AUTOSAR XML (schema 4-2-2)
package /C/DT
  data transformation set TC
    data transformation DT_CAN_LIN: transformer-chain=T1
    data transformation DT_Ethernet: transformer-chain=T2
    transformation technology T1: protocol=E2E, end-to-end-transformation-description{counter-offset=12, crc-offset=0, max-no-new-or-repeated-data=5, sync-counter-init=0}, transformer-class=SERIALIZER, version=1.0.0
    transformation technology T2: protocol=E2E, end-to-end-transformation-description{counter-offset=16, crc-offset=0, max-no-new-or-repeated-data=5, sync-counter-init=0}, transformer-class=SERIALIZER, version=1.0.0
package /C/Diagnostics
  elements:
    functional-request=FuncReq, physical-request=DoIP_Tp_ICU_PhyRequest, response=DoIP_Tp_ICU_PhyResponse
    functional-request=FuncReq, physical-request=PhyReq, response=DoIP_Tp_ICU_GW_AMP_PhyResponse
package /C/NetworkManagement
  nm config ADI
    can nm cluster ADI_CAN_ASR: communication-cluster=ADI_CAN, nm-cbv-position=1, nm-msg-cycle-time=0.5, nm-network-timeout=5, nm-nid-position=0, nm-repeat-message-time=0.5, nm-wait-bus-sleep-time=5
      can nm node AMP: nm-node-id=156, rx-nm-pdu=NmADIMessage_ASR, tx-nm-pdu=NmAMPMessage_ASR, nm-car-wake-up-filter-enabled=false, nm-car-wake-up-rx-enabled=false, nm-msg-cycle-offset=0, nm-range-config={lower-can-id=1435, upper-can-id=1436}
      can nm node ICU: controller=ADI_CAN_ICU, nm-coordinator-role=ACTIVE, nm-if-ecu=ICU_ADICAN_ASR, nm-node-id=155, rx-nm-pdu=NmAMPMessage_ASR, tx-nm-pdu=NmADIMessage_ASR, nm-car-wake-up-filter-enabled=false, nm-car-wake-up-rx-enabled=false, nm-range-config={lower-can-id=1435, upper-can-id=1436}
    nm-if-ecus:
      nm ecu ICU_ADICAN_ASR: ecu-instance=Infotainment_Control_Unit, nm-com-control-enabled=true, nm-coordinator={nm-active-coordinator=true, nm-shutdown-delay-timer=5}, nm-cycletime-main-function=0.05, nm-passive-mode-enabled=false
  nm config Ethernet_Backbone
    udp nm cluster Udp_Nm_Cluster1: communication-cluster=Ethernet_Backbone, nm-cbv-position=1, nm-message-timeout-time=5, nm-msg-cycle-time=0.5, nm-network-timeout=5, nm-nid-position=0, nm-remote-sleep-indication-time=0.5, nm-user-data-length=0, nm-wait-bus-sleep-time=0.75
      udp nm node ADI: controller=ETH_ICU, nm-if-ecu=ADI, nm-node-id=2, rx-nm-pdu=[NmTCUMessage, NmZA1Message], tx-nm-pdu=NmADIMessage, nm-msg-cycle-offset=0
    nm-if-ecus:
      nm ecu ADI: ecu-instance=Infotainment_Control_Unit, nm-coordinator=nm-shutdown-delay-timer=5, nm-cycletime-main-function=0.05, nm-passive-mode-enabled=false
package /C/PDUs
  dcm i pdu DiagFunctionalReq_DcmPDU: length=7, diag-pdu-type=DIAG-REQUEST
  dcm i pdu DiagReqAMP_DCMPDU: length=256, diag-pdu-type=DIAG-REQUEST
  general purpose pdu DoIP_ICU_UDP_Request: category=DoIP, length=8
  general purpose pdu DoIP_ICU_UDP_Response: category=DoIP, length=8
  pdu ACF_State01_PDU: length=2, transmission-mode-true-timing=cyclic-timing={time-offset=0, time-period=0.2}
    transmission-mode-conditions:
      data-filter=data-filter-type=ALWAYS, i-signal-in-i-pdu=BCameraFailureState
      data-filter=data-filter-type=ALWAYS, i-signal-in-i-pdu=NCameraSystemState
    mapping BCameraFailureState: i-signal=IBCameraFailureState, packing-byte-order=little-endian, start-position=0, transfer-property=PENDING
    mapping NCameraSystemState: i-signal=INCameraSystemState, packing-byte-order=little-endian, start-position=1, transfer-property=PENDING
  pdu ACUAlarmStatus_PDU: length=1, transmission-mode-true-timing=cyclic-timing={time-offset=0, time-period=0.1}
    transmission-mode-conditions:
      data-filter=data-filter-type=ALWAYS, i-signal-in-i-pdu=NAlarmStatus
      data-filter=data-filter-type=ALWAYS, i-signal-in-i-pdu=SignalIPDUAssignment21864
    mapping NAlarmStatus: i-signal=INAlarmStatus, packing-byte-order=big-endian, start-position=3, transfer-property=PENDING
    mapping SignalIPDUAssignment21864: i-signal=IBAlarmSystem, packing-byte-order=big-endian, start-position=7, transfer-property=PENDING
  i signal i pdu group ADI_ETH_BODYVLAN_BODY_ISignalIPduGroup_Rx: communication-direction=IN, i-signal-i-pdus=[BdyClusterMessage_PDU, CHMSLClusterMessage_PDU]
  i signal i pdu group ADI_ETH_BODYVLAN_BODY_ISignalIPduGroup_Tx: communication-direction=OUT, i-signal-i-pdus=[NDiffusedAirProfile_PDU, NDriverTempSlider_PDU]
  pdu HEC_MCM_PDU: length=1, transmission-mode-condition{data-filter=data-filter-type=ALWAYS, i-signal-in-i-pdu=Vehicle_SteerWheelPos_Status}, transmission-mode-true-timing=cyclic-timing={time-offset=0, time-period=1}
    mapping Vehicle_SteerWheelPos_Status: i-signal=IVehicle_SteerWheelPos_Status, packing-byte-order=big-endian, start-position=1, transfer-property=PENDING
  pdu HMA_State01_PDU: length=8, transmission-mode-true-timing=cyclic-timing={time-offset=0, time-period=0.04}
    transmission-mode-conditions:
      data-filter=data-filter-type=ALWAYS, i-signal-in-i-pdu=BIHC_HMA_Recommendation
      data-filter=data-filter-type=ALWAYS, i-signal-in-i-pdu=NHMA_State_CRC
    mapping NIHC_HMA_Status: i-signal=INIHC_HMA_Status, packing-byte-order=little-endian, start-position=0, transfer-property=PENDING
    mapping NIHC_HMANoHBReason: i-signal=INIHC_HMANoHBReason, packing-byte-order=little-endian, start-position=4, transfer-property=PENDING
  multiplexed i pdu NCarConfig: length=8, dynamic-part{segment-position{segment-byte-order=big-endian, segment-length=64, segment-position=7}, dynamic-part-alternatives=[{i-pdu=NCarConfig_MX1, selector-field-code=1}, {i-pdu=NCarConfig_MX2, selector-field-code=2}]}, selector-field-byte-order=big-endian, selector-field-length=3, selector-field-start-position=2
  multiplexed i pdu VIN: length=8, dynamic-part{segment-position{segment-byte-order=big-endian, segment-length=64, segment-position=7}, dynamic-part-alternatives=[{i-pdu=VIN_VIN_Bytes_8_14, selector-field-code=1}, {i-pdu=VIN_VIN_Bytes_1_7, initial-dynamic-part=true, selector-field-code=0}]}, selector-field-byte-order=big-endian, selector-field-length=8, selector-field-start-position=7
  n pdu DiagFunctionalReq_NPDU: length=8
  n pdu TestRespAMP_TP: length=8
  nm pdu NmADIMessage: length=2
  nm pdu NmADIMessage_ASR: length=8
  xcp pdu XCP_ESW_GW_RVC_Req_PDU: length=8
  xcp pdu XCP_ESW_GW_RVC_Resp_PDU: length=8
package /C/Signals
  i signal group INCruiseSwitch_Group: i-signal=[INCruiseSwitchChecksum, INCruiseSwitchCounter], system-signal-group=NCruiseSwitch_Group
  i signal group INDriverModeReq_Group: i-signal=[IBESPReducedRequested, INChassisModeEngaged], system-signal-group=NDriverModeReq_Group
  i signal IAMP_Audio_Balance_Status: init-value=Signal_AMP_Audio_Balance_Status:18, length=5, base-type=uint8_M, compu {phys=raw-9 for raw 0..18}, system-signal=AMP_Audio_Balance_Status
  i signal IAMP_Audio_Bass_Status: init-value=Signal_AMP_Audio_Bass_Status:18, length=5, base-type=uint8_M, compu-method=AMP_Audio_Bass_Status_NW, system-signal=AMP_Audio_Bass_Status
package /C/SystemSignals
  system signal AMP_Audio_Balance_Status: compu {phys=raw-9 for raw 0..18}
  system signal AMP_Audio_Bass_Status: compu-method=AMP_Audio_Bass_Status_NW
package /C/TP
  can tp config ADI_CAN: communication-cluster=ADI_CAN, can-tp-ecu=Infotainment_Control_Unit
    can tp channel CAN_Tp_Functional_Channel_ADICAN: channel-mode=FULL-DUPLEX-MODE
    can tp channel CAN_Tp_Physical_Channel_ADICAN: channel-mode=FULL-DUPLEX-MODE
    tp-connections:
      addressing-format=STANDARD, can-tp-channel=CAN_Tp_Functional_Channel_ADICAN, data-pdu=DiagFunctionalReq_NPDU, receiver=[Audio_Amplifier_Highline_ADI_CAN, Rear_View_Camera_ADI_CAN, Surround_View_Camera_Controller_ADI_CAN], ta-type=FUNCTIONAL, tp-sdu=DiagFunctionalReq_DcmPDU, transmitter=Infotainment_Control_Unit_ADI_CAN
      addressing-format=STANDARD, can-tp-channel=CAN_Tp_Physical_Channel_ADICAN, data-pdu=TestRespAMP_TP, flow-control-pdu=TesterReqAMP_TP, receiver=Infotainment_Control_Unit_ADI_CAN, ta-type=PHYSICAL, tp-sdu=DiagRespAMP_DCMPDU, transmitter=Audio_Amplifier_Highline_ADI_CAN
    can tp node Audio_Amplifier_Highline_ADI_CAN
    can tp node Infotainment_Control_Unit_ADI_CAN: connector=Infotainment_Control_Unit_ADI_CAN
  do ip tp config DoIP: communication-cluster=Ethernet_Backbone
    do ip logic address DoIP_ICU_Func: address=58368
    do ip logic address DoIP_ICU_GW_AMP_Func: address=58368
    do-ip-tp-connection do-ip-source-address=DoIP_ICU_GW_AMP_Phy, do-ip-target-address=OBDTester, tp-sdu=DoIpTp_ICU_AMP_PhysResp_DCMPDU_ETH:
      ident DoIP_Tp_ICU_GW_AMP_PhyResponse
    do-ip-tp-connection do-ip-source-address=DoIP_ICU_GW_RVC_Phy, do-ip-target-address=OBDTester, tp-sdu=DoIpTp_ICU_RVC_PhysResp_DCMPDU_ETH:
      ident DoIP_Tp_ICU_GW_RVC_PhyResponse
package /DataConstraints
  range Generic_Internal_Data_Constraint216: raw 0..12000
  range Generic_Internal_Data_Constraint2161: raw 0..12000
package /DataTypeMappingSets
  data type mapping set ADAS_HMI_Coordinator
    data-type-maps:
      application-data-type=BACCOvertakeBoost, implementation-data-type=uint8_M
      application-data-type=BACCOvertakePrevent, implementation-data-type=uint8_M
  data type mapping set ADI_Camera_AMP_Mgr
    data-type-maps:
      application-data-type=AMP_Audio_Balance_Status, implementation-data-type=uint8_M
      application-data-type=AMP_Audio_Bass_Status, implementation-data-type=uint8_M
package /DataTypes/ApplicationDataTypes
  application array data type N_DNS_Server: category=ARRAY, unit=NoUnit1
    element N_DNS_Server: category=ARRAY, type=N_DNS_Server_ArrayElement, array-size-semantics=FIXED-SIZE, max-number-of-elements=255
  application array data type N_DNS_Server_ArrayElement: category=ARRAY, unit=NoUnit1
    element N_DNS_Server_ArrayElement: category=VALUE, type=N_DNS_Server_Element, array-size-semantics=FIXED-SIZE, max-number-of-elements=4
  app type AMP_Audio_Balance_Status: category=VALUE, compu {phys=raw-9 for raw -9..9}, sw-intended-resolution=1.0, unit=NoUnit1
  app type AMP_Audio_Bass_Status: category=VALUE, compu-method=AMP_Audio_Bass_Status, sw-intended-resolution=1.0, unit=NoUnit1
  application record data type NCruiseSwitch_Group: category=STRUCTURE
    application record element NCruiseSwitchStatus: category=VALUE, type=NCruiseSwitchStatus
    application record element NIndicatorRStatus: category=VALUE, type=NIlluminationActiveStatus
  application record data type NDriverModeReq_Group: category=STRUCTURE
    application record element NESPOffRequested: category=VALUE, type=NESPOffRequested
    application record element NESPModeChangeReq: category=VALUE, type=N2ModeChangeRequested
package /DataTypes/BaseTypes
  sw addr method CONST_VOLATILE
  base type uint16_M: category=FIXED_LENGTH, base-type-size=16, base-type-encoding=NONE, mem-alignment=0, byte-order=big-endian, native-declaration=uint16
  base type uint32_M: category=FIXED_LENGTH, base-type-size=32, base-type-encoding=NONE, mem-alignment=0, byte-order=big-endian, native-declaration=uint32
package /DataTypes/ImplementationDataTypes
  impl type BESPReducedRequested: category=VALUE, sw-alignment=0, base-type=uint8_M, data-constr=uint81, sw-refresh-timing={cse-code=3, cse-code-factor=0}
  impl type NChassisModeEngaged: category=VALUE, sw-alignment=0, base-type=uint8_M, data-constr=uint8_M25, sw-refresh-timing={cse-code=3, cse-code-factor=0}
package /DataTypes/ModelManagement
  mode declaration group Body_LIN_Sch_Switch: category=ALPHABETIC_ORDER, initial-mode=BodyLINSchedule_Normal, on-transition-value=3
    mode BodyLINSchedule_LVHV: value=2
    mode BodyLINSchedule_Normal: value=1
    mode transition LVHV_to_Normal: entered-mode=BodyLINSchedule_Normal, exited-mode=BodyLINSchedule_LVHV
    mode transition Normal_to_LVHV: entered-mode=BodyLINSchedule_LVHV, exited-mode=BodyLINSchedule_Normal
  mode declaration group DriverInterface_LIN_Sch_Switch: category=ALPHABETIC_ORDER, initial-mode=DriverInterface_Normal, on-transition-value=4
    mode DriverInterface_Normal: value=1
    mode DriverInterface_SwcEvent1: value=2
    mode transition Normal_to_SwcEvent1: entered-mode=DriverInterface_SwcEvent1, exited-mode=DriverInterface_Normal
    mode transition SwcEvent1_to_SwcEvent2: entered-mode=DriverInterface_SwcEvent2, exited-mode=DriverInterface_SwcEvent1
package /DataTypes/Units
  unit A: display-name=A, factor-si-to-unit=0, offset-si-to-unit=0
  unit Amps: display-name=Amps, factor-si-to-unit=0, offset-si-to-unit=0
package /SoftwareTypes/ComponentTypes
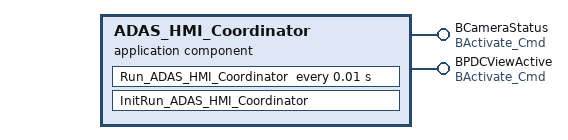
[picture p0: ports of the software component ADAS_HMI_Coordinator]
  application sw component type ADAS_HMI_Coordinator
    provide port BCameraStatus: nonqueued-sender-com-spec{data-element=Command, init-value=Zero:0}, provided-interface=BActivate_Cmd
    provide port BPDCViewActive: nonqueued-sender-com-spec{data-element=Command, init-value=Zero:0}, provided-interface=BActivate_Cmd
    behavior ADAS_HMI_Coordinator: data-type-mapping=ADAS_HMI_Coordinator
      init event ADAS_HMI_Coordinator_InitEv: start-on-event=InitRun_ADAS_HMI_Coordinator
      timing event ADAS_HMI_Coordinator_TimeEv: start-on-event=Run_ADAS_HMI_Coordinator, period=0.01
      runnable InitRun_ADAS_HMI_Coordinator
      runnable Run_ADAS_HMI_Coordinator
        data-read-access:
          access BACCAcousticWarning: accessed-variable=BACCAcousticWarning.Command
          access BACCOvertakeBoost: accessed-variable=BACCOvertakeBoost.BACCOvertakeBoost
        data-write-access:
          access BCameraStatus: accessed-variable=BCameraStatus.Command
          access BPDCViewActive: accessed-variable=BPDCViewActive.Command
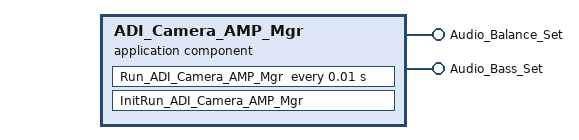
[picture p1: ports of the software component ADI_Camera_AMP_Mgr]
  application sw component type ADI_Camera_AMP_Mgr
    provide port Audio_Balance_Set: nonqueued-sender-com-spec{data-element=Audio_Balance_Set, init-value=Nine:9}, provided-interface=Audio_Balance_Set
    provide port Audio_Bass_Set: nonqueued-sender-com-spec{data-element=Audio_Bass_Set, init-value=Nine:9}, provided-interface=Audio_Bass_Set
    behavior ADI_Camera_AMP_Mgr: data-type-mapping=ADI_Camera_AMP_Mgr
      init event ADI_Camera_AMP_Mgr_InitEv: start-on-event=InitRun_ADI_Camera_AMP_Mgr
      timing event ADI_Camera_AMP_Mgr_TimeEv: start-on-event=Run_ADI_Camera_AMP_Mgr, period=0.01
      runnable InitRun_ADI_Camera_AMP_Mgr
      runnable Run_ADI_Camera_AMP_Mgr
        data-read-access:
          access AMP_Audio_Balance_Status: accessed-variable=AMP_Audio_Balance_Status.AMP_Audio_Balance_Status
          access AMP_Audio_Bass_Status: accessed-variable=AMP_Audio_Bass_Status.AMP_Audio_Bass_Status
        data-write-access:
          access Audio_Balance_Set: accessed-variable=Audio_Balance_Set.Audio_Balance_Set
          access Audio_Bass_Set: accessed-variable=Audio_Bass_Set.Audio_Bass_Set
package /SoftwareTypes/Interfaces
  client server interface BCheckForUpdate
    operation BCheckForUpdate
      arg ACKStatus_BCheckForUpdate: type=uint8_M, direction=OUT
  client server interface BgetSignalStrength
    operation BgetSignalStrength
      arg SignalStrength: type=uint8_M, direction=IN
      arg RSSI: type=uint8_M, direction=IN
  sender receiver interface AMP_Audio_Balance_Status
    data AMP_Audio_Balance_Status: type=uint8_M
  sender receiver interface AMP_Audio_Bass_Status
    data AMP_Audio_Bass_Status: type=uint8_M
package /System
  system System: category=ECU_EXTRACT
    system mapping Mapping: data-mappings={client-server-to-signal-mapping={client-server-operation=Infotainment_Control_UnitEcuComp.Some_IP_OTA_Client.BCheckForUpdate.BCheckForUpdate, return-signal=BCheckForUpdate_return}, client-server-to-signal-mapping={client-server-operation=Infotainment_Control_UnitEcuComp.Some_IP_OTA_Client.BpauseIVIDL.BpauseIVIDL, return-signal=BpauseIVIDL_return}, sender-receiver-to-signal-group-mapping={data-element=ADI_Ctrl_Mgr.Infotainment_Control_UnitEcuComp.NCruiseSwitch_Group.NCruiseSwitch_Group, signal-group=NCruiseSwitch_Group, type-mapping=sender-rec-record-type-mapping=record-element-mappings=[{implementation-record-element=NCruiseSwitchChecksum, system-signal=NCruiseSwitchChecksum}, {implementation-record-element=NIndicatorRStatus, system-signal=NIndicatorRStatus}]}, sender-receiver-to-signal-group-mapping={data-element=ADI_Ctrl_Mgr.Infotainment_Control_UnitEcuComp.NDriverModeReq_Group.NDriverModeReq_Group, signal-group=NDriverModeReq_Group, type-mapping=sender-rec-record-type-mapping=record-element-mappings=[{implementation-record-element=BESPReducedRequested, system-signal=BESPReducedRequested}, {implementation-record-element=NChassisModeEngaged, system-signal=NChassisModeEngaged}]}, sender-receiver-to-signal-mapping={data-element=ADI_Camera_AMP_Mgr.Infotainment_Control_UnitEcuComp.AMP_Audio_Balance_Status.AMP_Audio_Balance_Status, system-signal=AMP_Audio_Balance_Status}, sender-receiver-to-signal-mapping={data-element=ADI_Camera_AMP_Mgr.Infotainment_Control_UnitEcuComp.AMP_Audio_Bass_Status.AMP_Audio_Bass_Status, system-signal=AMP_Audio_Bass_Status}}
      sw-mappings:
        swc to ecu mapping Mapping_ADAS_HMI_Coordinator_Infotainment_Control_Unit: component=Infotainment_Control_UnitEcuComp.ADAS_HMI_Coordinator, ecu-instance=Infotainment_Control_Unit
        swc to ecu mapping Mapping_VIN_ICU_Infotainment_Control_Unit: component=Infotainment_Control_UnitEcuComp.VIN_ICU, ecu-instance=Infotainment_Control_Unit
    root-software-compositions:
      root sw composition prototype Infotainment_Control_UnitEcuComp: software-composition=Infotainment_Control_UnitEcuComp
package /Topo/Clusters
  can cluster ADI_CAN: baudrate=500000, protocol-name=CAN
    can physical channel ADI_CAN: comm-connectors=Infotainment_Control_Unit_ADI_CAN
      frame Message1: id 0x3B3, from Infotainment_Control_Unit, frame-length=8, can-addressing-mode=STANDARD, can-frame-rx-behavior=CAN-20, can-frame-tx-behavior=CAN-20
        carries pdu Message1_PDU: packing-byte-order=little-endian, start-position=0
      frame CSI_1_RVC: id 0x155, to Infotainment_Control_Unit, frame-length=8, can-addressing-mode=STANDARD, can-frame-rx-behavior=CAN-20, can-frame-tx-behavior=CAN-20
        carries pdu CSI_1_RVC_PDU: packing-byte-order=little-endian, start-position=0
      pdu triggering Message1_ADICAN_PDUT: pdu=Message1_PDU, from Infotainment_Control_Unit
      pdu triggering CSI_1_RVC_PDU_ADICAN_PDUT: pdu=CSI_1_RVC_PDU, to Infotainment_Control_Unit
  ethernet cluster Ethernet_Backbone: baudrate=100000000, coupling-port-connection{first-port=INT_ICU_SW_MICRO, second-port=ETH2}
    ethernet physical channel ETH_BODY: comm-connectors=ADI_ETH_BODY
      pdu triggering BdyClusterMessage_PDUT: pdu=BdyClusterMessage_PDU, to Infotainment_Control_Unit
      pdu triggering CHMSLClusterMessage_PDUT_ETH: pdu=CHMSLClusterMessage_PDU, to Infotainment_Control_Unit
      network endpoint ADI_Unicast_BODY_NEP: network-endpoint-addresses=ipv-6-configuration={assignment-priority=1, hop-count=0, ip-address-prefix-length=64, ipv-6-address=FD00:0:0:0:0:0:C0A8:A05, ipv-6-address-source=FIXED}, priority=1
      network endpoint VLAN_BODY_MULTICAST: network-endpoint-addresses=ipv-6-configuration={assignment-priority=1, hop-count=0, ipv-6-address=FF08:0:0:0:0:0:C0A8:A01, ipv-6-address-source=FIXED}, priority=1
      so-ad-config:
        socket connection bundle ADI_BODY_Output: socket-connection{client-port=VLAN_BODY_ADI_MULTICAST, pdus=[{header-id=40000, pdu-triggering=NHVACAutoButtonDrvr_PDUT}, {header-id=40017, pdu-triggering=NHVACDefrostButton_PDUT}]}, server-port=ADI_BODY_DATA_Tx
        socket connection bundle ZC1_BODY_Output: socket-connection{client-port=VLAN_BODY_ZC1_MULTICAST, pdus=[{header-id=40057, pdu-triggering=CHMSLClusterMessage_PDUT_ETH}, {header-id=40063, pdu-triggering=NRlcSafetyClusterMessage_PDT}]}, server-port=ZC1_BODY_DATA_Tx
        socket address ADI_BODY_DATA_Tx: connector=ADI_ETH_BODY
          application endpoint ADI_ETH_BODY: network-endpoint=ADI_Unicast_BODY_NEP, tp-configuration=udp-tp=udp-tp-port=port-number=10
        socket address VLAN_BODY_ADI_MULTICAST
          application endpoint ApplicationEndpoint145: network-endpoint=VLAN_BODY_MULTICAST, tp-configuration=udp-tp=udp-tp-port=port-number=10
      vlan VLAN_BODY: vlan-identifier=20
    ethernet physical channel ETH_CHASSIS: comm-connectors=ADI_ETH_CHASSIS
      pdu triggering ADI_ACF_NAV01_PDUT_ETH: pdu=ADI_ACF_NAV01_PDU, from Infotainment_Control_Unit
      pdu triggering ARF_Dynamic1_PDUT_ETH: pdu=ARF_Dynamic1_PDU, to Infotainment_Control_Unit
      network endpoint ADI_Unicast_CHASSIS_NEP: network-endpoint-addresses=ipv-6-configuration={assignment-priority=1, hop-count=0, ip-address-prefix-length=64, ipv-6-address=FD00:0:0:0:0:0:C0A8:A35, ipv-6-address-source=FIXED}, priority=1
      network endpoint ZC1_Unicast_CHASSIS_NEP: network-endpoint-addresses=ipv-6-configuration={assignment-priority=1, hop-count=0, ip-address-prefix-length=64, ipv-6-address=FD00:0:0:0:0:0:C0A8:A34, ipv-6-address-source=FIXED}, priority=1
      so-ad-config:
        socket connection bundle ZB1_CHASSIS_Output: socket-connection{client-port=VLAN_CHASSIS_ZB1_MULTICAST, pdus=[{header-id=40115, pdu-triggering=PCS_1_PDUT_ETH}, header-id=40116]}, server-port=ZB1_CHASSIS_DATA_Tx
        socket connection bundle ZB2_CHASSIS_Output: socket-connection{client-port=VLAN_CHASSIS_ZB2_MULTICAST, pdus=[{header-id=40133, pdu-triggering=TPMSNWOutput_PDUT_ETH}, {header-id=40134, pdu-triggering=TPMS_Main_Status_PDUT_ETH}]}, server-port=ZB2_CHASSIS_DATA_Tx
        socket address ADI_CHASSIS_DATA_Tx: connector=ADI_ETH_CHASSIS
          application endpoint ApplicationEndpoint75: network-endpoint=ADI_Unicast_CHASSIS_NEP, tp-configuration=udp-tp=udp-tp-port=port-number=2
        socket address VLAN_CHASSIS_ADI_MULTICAST
          application endpoint ApplicationEndpoint143: network-endpoint=VLAN_CHASSIS_MULTICAST, tp-configuration=udp-tp=udp-tp-port=port-number=2
      vlan VLAN_CHASSIS: vlan-identifier=30
package /Topo/HWComponents
  coupling element ICU_Coupling_Element: communication-cluster=Ethernet_Backbone, coupling-type=SWITCH, ecu-instance=Infotainment_Control_Unit
    coupling port ETH_ICU_OABR_2: vlan-memberships=[{send-activity=SENT-TAGGED, vlan=ETH_BODY}, {send-activity=SENT-TAGGED, vlan=ETH_CHASSIS}]
    coupling port INT_ICU_SW_MICRO: default-vlan=ETH_POWERTRAIN, vlan-memberships=[{send-activity=SENT-TAGGED, vlan=ETH_BODY}, {send-activity=SENT-TAGGED, vlan=ETH_CHASSIS}]
  ecu instance Infotainment_Control_Unit: associated-com-i-pdu-group=[ADI_ETH_BODYVLAN_BODY_ISignalIPduGroup_Rx, ADI_ETH_BODYVLAN_BODY_ISignalIPduGroup_Tx], sleep-mode-supported=false, wake-up-over-bus-supported=false
    can communication controller ADI_CAN_ICU
    ethernet communication controller ETH_ICU: mac-unicast-address=AA:BB:CC:DD:00:06
      coupling port ETH2: coupling-port-speed=0, physical-layer-type=BROAD-R-REACH, vlan-membership=ETH_POWERTRAIN
    can communication connector Infotainment_Control_Unit_ADI_CAN: comm-controller=ADI_CAN_ICU
    ethernet communication connector ADI_ETH_BODY: comm-controller=ETH_ICU, network-endpoint=[ADI_Unicast_BODY_NEP, VLAN_BODY_MULTICAST]
    ethernet communication connector ADI_ETH_CHASSIS: comm-controller=ETH_ICU, network-endpoint=[ADI_Unicast_CHASSIS_NEP, VLAN_CHASSIS_MULTICAST]
  gateway GATEWAY: ecu=Infotainment_Control_Unit
    i-pdu-mappings:
      source-i-pdu=Diag_Response_AMP_PDUT, target-i-pdu=DoIpTp_ICU_AMP_PhysResp_DCMPDU_ETH
      source-i-pdu=Diag_Response_AMP_PDUT, target-i-pdu=InternalTesterPhyRespAMP_DCMPDU
    signal-mappings:
      source-signal=NRVCSystemStatus_ADICAN_SigTxn, target-signal=NRVCSystemStatus
      source-signal=NSVCSystemStatus_ADICAN_SigTxn, target-signal=NSVCSystemStatus
